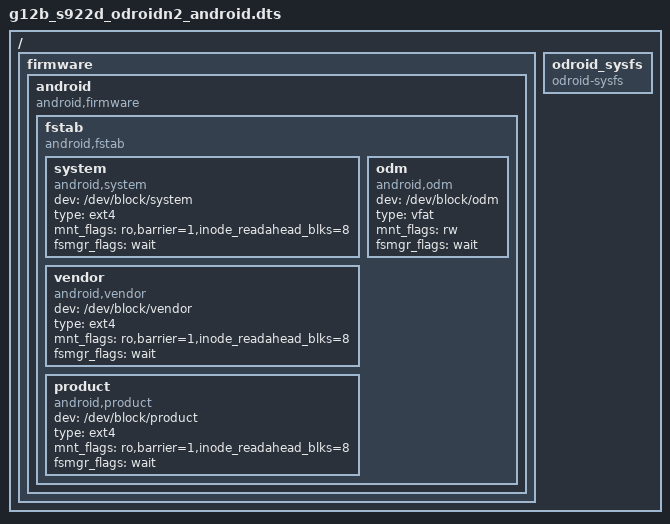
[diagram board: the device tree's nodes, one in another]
/*
 * arch/arm64/boot/dts/amlogic/meson64_odroidc3_android.dts
 *
 * Copyright (C) 2018 Hardkernel Co., Ltd. All rights reserved.
 *
 * This program is free software; you can redistribute it and/or modify
 * it under the terms of the GNU General Public License as published by
 * the Free Software Foundation; either version 2 of the License, or
 * (at your option) any later version.
 *
 * This program is distributed in the hope that it will be useful, but WITHOUT
 * ANY WARRANTY; without even the implied warranty of MERCHANTABILITY or
 * FITNESS FOR A PARTICULAR PURPOSE.  See the GNU General Public License for
 * more details.
 *
 */

#include "g12b_s922d_odroidn2.dts"

/ {
	firmware {
		android {
			compatible = "android,firmware";
			fstab {
				compatible = "android,fstab";
				system {
					compatible = "android,system";
					dev = "/dev/block/system";
					type = "ext4";
					mnt_flags = "ro,barrier=1,inode_readahead_blks=8";
					fsmgr_flags = "wait";
				};
				vendor {
					compatible = "android,vendor";
					dev = "/dev/block/vendor";
					type = "ext4";
					mnt_flags = "ro,barrier=1,inode_readahead_blks=8";
					fsmgr_flags = "wait";
				};
				odm {
					compatible = "android,odm";
					dev = "/dev/block/odm";
					type = "vfat";
					mnt_flags = "rw";
					fsmgr_flags = "wait";
				};
				product {
					compatible = "android,product";
					dev = "/dev/block/product";
					type = "ext4";
					mnt_flags = "ro,barrier=1,inode_readahead_blks=8";
					fsmgr_flags = "wait";
				};
			};
		};
	};

	odroid_sysfs {
		compatible = "odroid-sysfs";
		status = "okay";
	};
};
